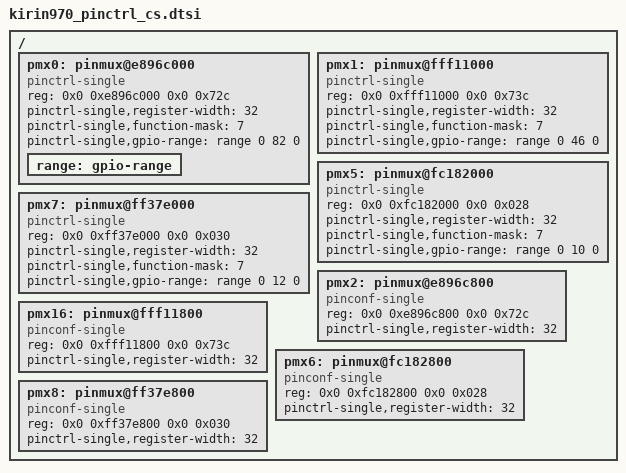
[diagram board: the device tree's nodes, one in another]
/*
 * Hisilicon Ltd. Kirin970_CS SoC
 *
 * Copyright (C) 2012-2014 Hisilicon Ltd.
 *
 * This program is free software; you can redistribute it and/or modify
 * it under the terms of the GNU General Public License version 2 as
 * publishhed by the Free Software Foundation.
 */

/ {
	pmx0: pinmux@e896c000 {
		compatible = "pinctrl-single", "pinctrl-single0";
		reg = <0x0 0xe896c000 0x0 0x72c>;
		#gpio-range-cells = <3>;
		//ranges;
		pinctrl-single,register-width = <32>;
		pinctrl-single,function-mask = <7>;
		/* pin base, nr pins & gpio function */
		pinctrl-single,gpio-range = <&range 0 82 0>;
		range: gpio-range {
			#pinctrl-single,gpio-range-cells = <3>;
		};
	};

	pmx1: pinmux@fff11000 {
		compatible = "pinctrl-single", "pinctrl-single1";
		reg = <0x0 0xfff11000 0x0 0x73c>;
		#gpio-range-cells = <3>;
		//ranges;
		pinctrl-single,register-width = <32>;
		pinctrl-single,function-mask = <7>;
		/* pin base, nr pins & gpio function */
		pinctrl-single,gpio-range = <&range 0 46 0>;
	};

	pmx5: pinmux@fc182000 {
		compatible = "pinctrl-single", "pinctrl-single5";
		reg = <0x0 0xfc182000 0x0 0x028>;
		#gpio-range-cells = <3>;
		pinctrl-single,register-width = <32>;
		pinctrl-single,function-mask = <7>;
		/* pin base, nr pins & gpio function */
		pinctrl-single,gpio-range = <&range 0 10 0>;
	};

	pmx7: pinmux@ff37e000 {
		compatible = "pinctrl-single", "pinctrl-single7";
		reg = <0x0 0xff37e000 0x0 0x030>;
		#gpio-range-cells = <3>;
		pinctrl-single,register-width = <32>;
		pinctrl-single,function-mask = <7>;
		/* pin base, nr pins & gpio function */
		pinctrl-single,gpio-range = <&range 0 12 0>;
	};

	pmx2: pinmux@e896c800 {
		compatible = "pinconf-single", "pinctrl-single2";
		reg = <0x0 0xe896c800 0x0 0x72c>;
		pinctrl-single,register-width = <32>;
	};

	pmx16: pinmux@fff11800 {
		compatible = "pinconf-single", "pinctrl-single16";
		reg = <0x0 0xfff11800 0x0 0x73c>;
		pinctrl-single,register-width = <32>;
	};

	pmx6: pinmux@fc182800 {
		compatible = "pinconf-single", "pinctrl-single6";
		reg = <0x0 0xfc182800 0x0 0x028>;
		pinctrl-single,register-width = <32>;
	};

	pmx8: pinmux@ff37e800 {
		compatible = "pinconf-single", "pinctrl-single8";
		reg = <0x0 0xff37e800 0x0 0x030>;
		pinctrl-single,register-width = <32>;
	};
};
